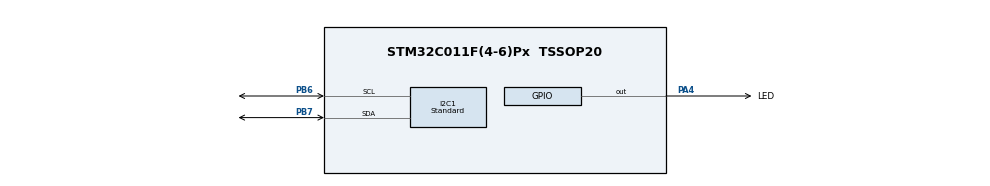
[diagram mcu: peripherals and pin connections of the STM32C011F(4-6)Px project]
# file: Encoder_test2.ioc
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Dma.I2C1_RX.1.Direction=DMA_PERIPH_TO_MEMORY
Dma.I2C1_RX.1.EventEnable=DISABLE
Dma.I2C1_RX.1.Instance=DMA1_Channel2
Dma.I2C1_RX.1.MemDataAlignment=DMA_MDATAALIGN_BYTE
Dma.I2C1_RX.1.MemInc=DMA_MINC_ENABLE
Dma.I2C1_RX.1.Mode=DMA_CIRCULAR
Dma.I2C1_RX.1.PeriphDataAlignment=DMA_PDATAALIGN_BYTE
Dma.I2C1_RX.1.PeriphInc=DMA_PINC_DISABLE
Dma.I2C1_RX.1.Polarity=HAL_DMAMUX_REQ_GEN_RISING
Dma.I2C1_RX.1.Priority=DMA_PRIORITY_HIGH
Dma.I2C1_RX.1.RequestNumber=1
Dma.I2C1_RX.1.SignalID=NONE
Dma.I2C1_RX.1.SyncEnable=DISABLE
Dma.I2C1_RX.1.SyncPolarity=HAL_DMAMUX_SYNC_NO_EVENT
Dma.I2C1_RX.1.SyncRequestNumber=1
Dma.I2C1_RX.1.SyncSignalID=NONE
Dma.I2C1_TX.0.Direction=DMA_MEMORY_TO_PERIPH
Dma.I2C1_TX.0.EventEnable=DISABLE
Dma.I2C1_TX.0.Instance=DMA1_Channel1
Dma.I2C1_TX.0.MemDataAlignment=DMA_MDATAALIGN_BYTE
Dma.I2C1_TX.0.MemInc=DMA_MINC_ENABLE
Dma.I2C1_TX.0.Mode=DMA_CIRCULAR
Dma.I2C1_TX.0.PeriphDataAlignment=DMA_PDATAALIGN_BYTE
Dma.I2C1_TX.0.PeriphInc=DMA_PINC_DISABLE
Dma.I2C1_TX.0.Polarity=HAL_DMAMUX_REQ_GEN_RISING
Dma.I2C1_TX.0.Priority=DMA_PRIORITY_MEDIUM
Dma.I2C1_TX.0.RequestNumber=1
Dma.I2C1_TX.0.SignalID=NONE
Dma.I2C1_TX.0.SyncEnable=DISABLE
Dma.I2C1_TX.0.SyncPolarity=HAL_DMAMUX_SYNC_NO_EVENT
Dma.I2C1_TX.0.SyncRequestNumber=1
Dma.I2C1_TX.0.SyncSignalID=NONE
Dma.Request0=I2C1_TX
Dma.Request1=I2C1_RX
I2C1.I2C_Speed_Mode=I2C_Standard
I2C1.Timing=0x00303D5B
Mcu.Family=STM32C0
Mcu.Name=STM32C011F(4-6)Px
Mcu.Package=TSSOP20
NVIC.DMA1_Channel1_IRQn=true\:0\:0\:false\:false\:true\:false\:true\:true
NVIC.DMA1_Channel2_3_IRQn=true\:0\:0\:false\:false\:true\:false\:true\:true
PA4.GPIO_Label=LED
PA4.Signal=GPIO_Output
PB6.Mode=I2C
PB6.Signal=I2C1_SCL
PB7.Mode=I2C
PB7.Signal=I2C1_SDA
PC14-OSCX_IN\ (PC14).Mode=HSE-External-Oscillator-REMAPPED
PC14-OSCX_IN\ (PC14).Signal=RCC_OSCX_IN
PC15-OSCX_OUT\ (PC15).Mode=HSE-External-Oscillator-REMAPPED
PC15-OSCX_OUT\ (PC15).Signal=RCC_OSCX_OUT
ProjectManager.HeapSize=0x200
ProjectManager.StackSize=0x400
ProjectManager.TargetToolchain=STM32CubeIDE
RCC.ADCFreq_Value=16000000
RCC.AHBFreq_Value=16000000
RCC.CortexFreq_Value=16000000
RCC.EXTERNAL_CLOCK_VALUE=12288000
RCC.HCLKFreq_Value=16000000
RCC.HSE_VALUE=16000000
RCC.HSI_VALUE=48000000
RCC.LSE_VALUE=32768
RCC.SYSCLKFreq_VALUE=16000000
RCC.SYSCLKSource=RCC_SYSCLKSOURCE_HSE
board=custom

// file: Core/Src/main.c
/* USER CODE BEGIN Header */
/**
  ******************************************************************************
  * @file           : main.c
  * @brief          : Main program body
  ******************************************************************************
  * @attention
  *
  * Copyright (c) 2024 STMicroelectronics.
  * All rights reserved.
  *
  * This software is licensed under terms that can be found in the LICENSE file
  * in the root directory of this software component.
  * If no LICENSE file comes with this software, it is provided AS-IS.
  *
  ******************************************************************************
  */
/* USER CODE END Header */
#include "main.h"

/* USER CODE BEGIN Includes */
#include <math.h>
#include <stdio.h>
#include <stdlib.h>
/* USER CODE END Includes */

I2C_HandleTypeDef hi2c1;
DMA_HandleTypeDef hdma_i2c1_tx;
DMA_HandleTypeDef hdma_i2c1_rx;

/* USER CODE BEGIN PV */
//volatile uint32_t m_counter;
/* USER CODE END PV */

void SystemClock_Config(void);
static void MX_GPIO_Init(void);
static void MX_DMA_Init(void);
static void MX_I2C1_Init(void);

/* USER CODE BEGIN 0 */

//extern void initialise_monitor_handles(void);

//void HAL_TIM_PeriodElapsedCallback(TIM_HandleTypeDef *htim)
//{
//    if (htim == &htim3){
//        m_counter++;
//    }
//}
/* USER CODE END 0 */

int main(void)
{

  /* USER CODE BEGIN 1 */
//  initialise_monitor_handles();
  /* USER CODE END 1 */

  /* MCU Configuration--------------------------------------------------------*/

  /* Reset of all peripherals, Initializes the Flash interface and the Systick. */
  HAL_Init();

  /* Configure the system clock */
  SystemClock_Config();

  /* Initialize all configured peripherals */
  MX_GPIO_Init();
  MX_DMA_Init();
  MX_I2C1_Init();
  /* USER CODE BEGIN 2 */
//  HAL_TIM_Base_Start_IT(&htim3);

  uint16_t AS5600_ADDR = 0x36 << 1;
  uint8_t ANGLE_ADDR = 0x0E;
  uint8_t rcvBuf[128] = {0,0};

  long totalAng = 0;
  long ptotalAng = 0;
  uint16_t Angle;
  uint16_t pAngle;

  /* USER CODE END 2 */

  /* Infinite loop */
  /* USER CODE BEGIN WHILE */
  HAL_I2C_Master_Transmit_DMA (&hi2c1, AS5600_ADDR, &ANGLE_ADDR, 1);
  HAL_I2C_Master_Receive_DMA (&hi2c1, AS5600_ADDR, rcvBuf, sizeof(rcvBuf));

//  HAL_I2C_Master_Transmit(&hi2c1, AS5600_ADDR, &ANGLE_ADDR, 1, 1000);
//  HAL_I2C_Master_Receive(&hi2c1, AS5600_ADDR, rcvBuf, 2, 1000);

  pAngle = rcvBuf[0]*256 + rcvBuf[1];
  ptotalAng = pAngle;

//  uint32_t p_counter;
//  p_counter = m_counter;

  while (1)
  {
    /* USER CODE END WHILE */

    /* USER CODE BEGIN 3 */

	 	HAL_I2C_Master_Transmit(&hi2c1, AS5600_ADDR, &ANGLE_ADDR, 1, 1000);
	 	HAL_I2C_Master_Receive(&hi2c1, AS5600_ADDR, rcvBuf, 2, 1000);
	 	Angle = rcvBuf[0]*256 + rcvBuf[1];

	    if(Angle-pAngle>0 && abs(Angle-pAngle)<4000){
	        totalAng = ptotalAng + (Angle-pAngle);
	    }else if(Angle-pAngle<0 && abs(Angle-pAngle)<4000){
	        totalAng = ptotalAng + (Angle-pAngle);
	    }else if(Angle-pAngle>0 && abs(Angle-pAngle)>4000){
	        totalAng = ptotalAng - ((4095-Angle)+pAngle);
	    }else if(Angle-pAngle<0 && abs(Angle-pAngle)>4000){
	        totalAng = ptotalAng + Angle + (4095-pAngle);
	    }else{
	        totalAng = ptotalAng;
	    }

//	    speed = (totalAng - ptotalAng)*7666/ dtime;
//	    speed = (0.8*speed) + (0.2*pspeed);

	    ptotalAng = totalAng;
	    pAngle = Angle;
//	    pspeed = speed;

//	    if(m_counter - p_counter > 1000){
//	    	printf("%ld\n", totalAng);
////	    	printf("%ld\n", m_counter);
	    	HAL_GPIO_TogglePin(LED_GPIO_Port, LED_Pin);
//	    	p_counter = m_counter;
//	    }
//	    else{}
  }
  /* USER CODE END 3 */
}

void SystemClock_Config(void)
{
  RCC_OscInitTypeDef RCC_OscInitStruct = {0};
  RCC_ClkInitTypeDef RCC_ClkInitStruct = {0};

  /** Initializes the RCC Oscillators according to the specified parameters
  * in the RCC_OscInitTypeDef structure.
  */
  RCC_OscInitStruct.OscillatorType = RCC_OSCILLATORTYPE_HSE;
  RCC_OscInitStruct.HSEState = RCC_HSE_ON;
  if (HAL_RCC_OscConfig(&RCC_OscInitStruct) != HAL_OK)
  {
    Error_Handler();
  }

  /** Initializes the CPU, AHB and APB buses clocks
  */
  RCC_ClkInitStruct.ClockType = RCC_CLOCKTYPE_HCLK|RCC_CLOCKTYPE_SYSCLK
                              |RCC_CLOCKTYPE_PCLK1;
  RCC_ClkInitStruct.SYSCLKSource = RCC_SYSCLKSOURCE_HSE;
  RCC_ClkInitStruct.SYSCLKDivider = RCC_SYSCLK_DIV1;
  RCC_ClkInitStruct.AHBCLKDivider = RCC_HCLK_DIV1;
  RCC_ClkInitStruct.APB1CLKDivider = RCC_APB1_DIV1;

  if (HAL_RCC_ClockConfig(&RCC_ClkInitStruct, FLASH_LATENCY_0) != HAL_OK)
  {
    Error_Handler();
  }
}

static void MX_I2C1_Init(void)
{

  hi2c1.Instance = I2C1;
  hi2c1.Init.Timing = 0x00303D5B;
  hi2c1.Init.OwnAddress1 = 0;
  hi2c1.Init.AddressingMode = I2C_ADDRESSINGMODE_7BIT;
  hi2c1.Init.DualAddressMode = I2C_DUALADDRESS_DISABLE;
  hi2c1.Init.OwnAddress2 = 0;
  hi2c1.Init.OwnAddress2Masks = I2C_OA2_NOMASK;
  hi2c1.Init.GeneralCallMode = I2C_GENERALCALL_DISABLE;
  hi2c1.Init.NoStretchMode = I2C_NOSTRETCH_DISABLE;
  if (HAL_I2C_Init(&hi2c1) != HAL_OK)
  {
    Error_Handler();
  }

  /** Configure Analogue filter
  */
  if (HAL_I2CEx_ConfigAnalogFilter(&hi2c1, I2C_ANALOGFILTER_ENABLE) != HAL_OK)
  {
    Error_Handler();
  }

  /** Configure Digital filter
  */
  if (HAL_I2CEx_ConfigDigitalFilter(&hi2c1, 0) != HAL_OK)
  {
    Error_Handler();
  }

}

static void MX_DMA_Init(void)
{

  /* DMA controller clock enable */
  __HAL_RCC_DMA1_CLK_ENABLE();

  /* DMA interrupt init */
  /* DMA1_Channel1_IRQn interrupt configuration */
  HAL_NVIC_SetPriority(DMA1_Channel1_IRQn, 0, 0);
  HAL_NVIC_EnableIRQ(DMA1_Channel1_IRQn);
  /* DMA1_Channel2_3_IRQn interrupt configuration */
  HAL_NVIC_SetPriority(DMA1_Channel2_3_IRQn, 0, 0);
  HAL_NVIC_EnableIRQ(DMA1_Channel2_3_IRQn);

}

static void MX_GPIO_Init(void)
{
  GPIO_InitTypeDef GPIO_InitStruct = {0};

  /* GPIO Ports Clock Enable */
  __HAL_RCC_GPIOB_CLK_ENABLE();
  __HAL_RCC_GPIOC_CLK_ENABLE();
  __HAL_RCC_GPIOA_CLK_ENABLE();

  /*Configure GPIO pin Output Level */
  HAL_GPIO_WritePin(LED_GPIO_Port, LED_Pin, GPIO_PIN_RESET);

  /*Configure GPIO pin : LED_Pin */
  GPIO_InitStruct.Pin = LED_Pin;
  GPIO_InitStruct.Mode = GPIO_MODE_OUTPUT_PP;
  GPIO_InitStruct.Pull = GPIO_NOPULL;
  GPIO_InitStruct.Speed = GPIO_SPEED_FREQ_LOW;
  HAL_GPIO_Init(LED_GPIO_Port, &GPIO_InitStruct);

}

void Error_Handler(void)
{
  __disable_irq();
  while (1)
  {
  }
}
